# STM32H503 register map
File version: 1.5
CPU: CM33 r0p0, little endian, MPU, FPU, 4 interrupt priority bits
Registers are 32-bit, read-write, reset 0x0 unless marked. A register's access mark holds for its fields unless they carry their own. Offsets are from the block's base; [hi:lo] are bit positions; 'fields as' and 'values as' point back to an identical list.

## RCC (part 2 of 2) — Reset and clock controller
Base 0x44020C00
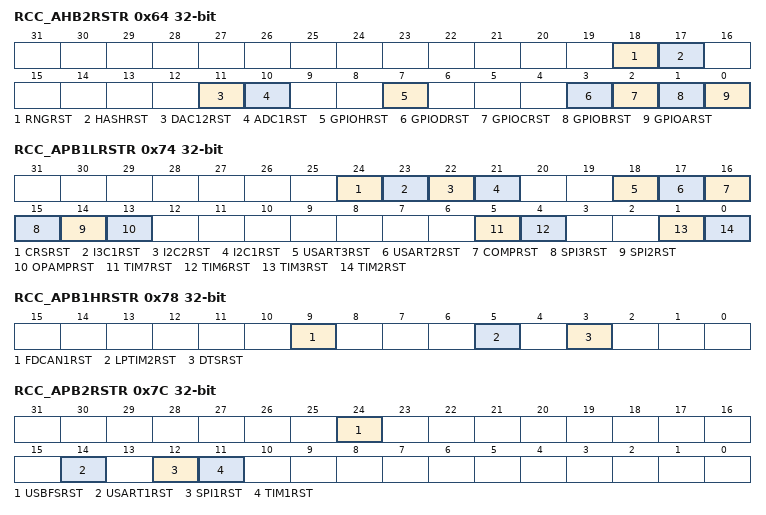
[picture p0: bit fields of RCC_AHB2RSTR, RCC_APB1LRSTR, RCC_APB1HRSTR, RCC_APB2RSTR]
0x64 RCC_AHB2RSTR — RCC AHB2 peripheral reset register
  [18] RNGRST — RNG block reset Set and reset by software.
    0=does not reset RNG block (default after reset); 1=resets RNG block
  [17] HASHRST — HASH block reset Set and reset by software.
    0=does not reset HASH block (default after reset); 1=resets HASH block
  [11] DAC12RST — DAC block reset Set and reset by software.
    0=does not reset DAC block (default after reset); 1=resets DAC block
  [10] ADC1RST — ADC1 block reset Set and reset by software.
    0=does not reset ADC1 block (default after reset); 1=resets ADC1 block
  [7] GPIOHRST — GPIOH block reset Set and reset by software.
    0=does not reset the GPIOH block (default after reset); 1=resets the GPIOH block
  [3] GPIODRST — GPIOD block reset Set and reset by software.
    0=does not reset the GPIOD block (default after reset); 1=resets the GPIOD block
  [2] GPIOCRST — GPIOC block reset Set and reset by software.
    0=does not reset the GPIOC block (default after reset); 1=resets the GPIOC block
  [1] GPIOBRST — GPIOB block reset Set and reset by software.
    0=does not reset the GPIOB block (default after reset); 1=resets the GPIOB block
  [0] GPIOARST — GPIOA block reset Set and reset by software.
    0=does not reset the GPIOA block (default after reset); 1=resets the GPIOA block
0x74 RCC_APB1LRSTR — RCC APB1 peripheral low reset register
  [24] CRSRST — CRS block reset Set and reset by software.
    0=does not reset the CRS block (default after reset); 1=resets the CRS block
  [23] I3C1RST — I3C1 block reset Set and reset by software.
    0=does not reset the I3C1 block (default after reset); 1=resets the I3C1 block
  [22] I2C2RST — I2C2 block reset Set and reset by software.
    0=does not reset the I2C2 block (default after reset); 1=resets the I2C2 block
  [21] I2C1RST — I2C1 block reset Set and reset by software.
    0=does not reset the I2C1 block (default after reset); 1=resets the I2C1 block
  [18] USART3RST — USART3 block reset Set and reset by software.
    0=does not reset the USART3 block (default after reset); 1=resets the USART3 block
  [17] USART2RST — USART2 block reset Set and reset by software.
    0=does not reset the USART2 block (default after reset); 1=resets the USART2 block
  [16] COMPRST — COMP block reset Set and reset by software.
    0=does not reset the COMP block (default after reset); 1=resets the COMP block
  [15] SPI3RST — SPI3 block reset Set and reset by software.
    0=does not reset the SPI3 block (default after reset); 1=resets the SPI3 block
  [14] SPI2RST — SPI2 block reset Set and reset by software.
    0=does not reset the SPI2 block (default after reset); 1=resets the SPI2 block
  [13] OPAMPRST — OPAMP block reset Set and reset by software.
    0=does not reset the OPAMP block (default after reset); 1=resets the OPAMP block
  [5] TIM7RST — TIM7 block reset Set and reset by software.
    0=does not reset the TIM7 block (default after reset); 1=resets the TIM7 block
  [4] TIM6RST — TIM6 block reset Set and reset by software.
    0=does not reset the TIM6 block (default after reset); 1=resets the TIM6 block
  [1] TIM3RST — TIM3 block reset Set and reset by software.
    0=does not reset the TIM3 block (default after reset); 1=resets the TIM3 block
  [0] TIM2RST — TIM2 block reset Set and reset by software.
    0=does not reset the TIM2 block (default after reset); 1=resets the TIM2 block
0x78 RCC_APB1HRSTR — RCC APB1 peripheral high reset register
  [9] FDCAN1RST — FDCAN1 block reset Set and reset by software.
    0=does not reset the FDCAN1 block (default after reset); 1=resets the FDCAN1 block
  [5] LPTIM2RST — LPTIM2 block reset Set and reset by software.
    0=does not reset the LPTIM2 block (default after reset); 1=resets the LPTIM2 block
  [3] DTSRST — DTS block reset Set and reset by software.
    0=does not reset the DTS block (default after reset); 1=resets the DTS block
0x7C RCC_APB2RSTR — RCC APB2 peripheral reset register
  [24] USBFSRST — USBFS block reset Set and reset by software.
    0=does not reset the USBFS block (default after reset); 1=resets the USBFS block
  [14] USART1RST — USART1 block reset Set and reset by software.
    0=does not reset the USART1 block (default after reset); 1=resets the USART1 block
  [12] SPI1RST — SPI1 block reset Set and reset by software.
    0=does not reset the SPI1 block (default after reset); 1=resets the SPI1 block
  [11] TIM1RST — TIM1 block reset Set and reset by software.
    0=does not reset the TIM1 block (default after reset); 1=resets the TIM1 block
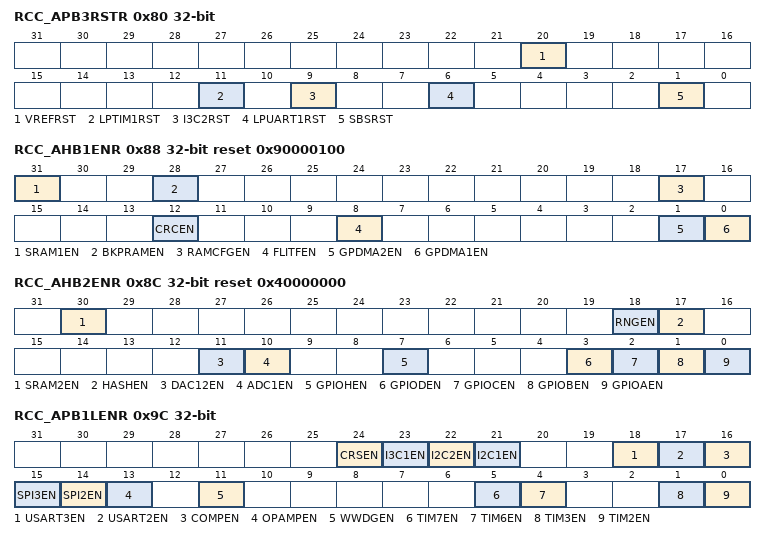
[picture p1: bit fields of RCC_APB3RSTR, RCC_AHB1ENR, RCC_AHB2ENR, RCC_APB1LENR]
0x80 RCC_APB3RSTR — RCC APB3 peripheral reset register
  [20] VREFRST — VREF block reset Set and reset by software.
    0=does not reset the VREF block (default after reset); 1=resets the VREF block
  [11] LPTIM1RST — LPTIM1 block reset Set and reset by software.
    0=does not reset the LPTIM1 block (default after reset); 1=resets the LPTIM1 block
  [9] I3C2RST — I3C2RST block reset Set and reset by software.
    0=does not reset the I3C2RST block (default after reset); 1=resets the I3C2RST block
  [6] LPUART1RST — LPUART1 block reset Set and reset by software.
    0=does not reset the LPUART1 block (default after reset); 1=resets the LPUART1 block
  [1] SBSRST — SBS block reset Set and reset by software.
    0=does not reset the SBS block (default after reset); 1=resets the SBS block
0x88 RCC_AHB1ENR reset 0x90000100 — RCC AHB1 peripherals clock register
  [31] SRAM1EN — SRAM1 clock enable Set and reset by software.
    0=SRAM1 clock disabled; 1=SRAM1 clock enabled (default after reset)
  [28] BKPRAMEN — BKPRAM clock enable Set and reset by software
    0=BKPRAM peripheral clock disabled (default after reset); 1=BKPRAM peripheral clock enabled
  [17] RAMCFGEN — RAMCFG clock enable Set and reset by software.
    0=RAMCFG peripheral clock disabled (default after reset); 1=RAMCFG peripheral clock enabled
  [12] CRCEN — CRC clock enable Set and reset by software.
    0=CRC peripheral clock disabled (default after reset); 1=CRC peripheral clock enabled
  [8] FLITFEN — Flash interface clock enable Set and reset by software.
    0=FLASH interface clock disabled; 1=FLASH interface clock enabled (default after reset)
  [1] GPDMA2EN — GPDMA2 clock enable Set and reset by software.
    0=GPDMA2 peripheral clock disabled (default after reset); 1=GPDMA2 peripheral clock enabled
  [0] GPDMA1EN — GPDMA1 clock enable Set and reset by software.
    0=GPDMA1 peripheral clock disabled (default after reset); 1=GPDMA1 peripheral clock enabled
0x8C RCC_AHB2ENR reset 0x40000000 — RCC AHB2 peripheral clock register
  [30] SRAM2EN — SRAM2 clock enable Set and reset by software.
    0=SRAM2 clock disabled; 1=SRAM2 clock enabled (default after reset)
  [18] RNGEN — RNG clock enable Set and reset by software.
    0=RNG peripheral clock disabled (default after reset); 1=RNG peripheral clock enabled
  [17] HASHEN — HASH clock enable Set and reset by software.
    0=HASH peripheral clock disabled (default after reset); 1=HASH peripheral clock enabled
  [11] DAC12EN — DAC clock enable Set and reset by software.
    0=DAC peripheral clock disabled (default after reset); 1=DAC peripheral clock enabled
  [10] ADC1EN — ADC1 peripherals clock enabled Set and reset by software.
    0=ADC1 peripherals clock disabled (default after reset); 1=ADC1 peripherals clock enabled
  [7] GPIOHEN — GPIOH clock enable Set and reset by software.
    0=GPIOH peripheral clock disabled (default after reset); 1=GPIOH peripheral clock enabled
  [3] GPIODEN — GPIOD clock enable Set and reset by software.
    0=GPIOD peripheral clock disabled (default after reset); 1=GPIOD peripheral clock enabled
  [2] GPIOCEN — GPIOC clock enable Set and reset by software.
    0=GPIOC peripheral clock disabled (default after reset); 1=GPIOC peripheral clock enabled
  [1] GPIOBEN — GPIOB clock enable Set and reset by software.
    0=GPIOB peripheral clock disabled (default after reset); 1=GPIOB peripheral clock enabled
  [0] GPIOAEN — GPIOA clock enable Set and reset by software.
    0=GPIOA peripheral clock disabled (default after reset); 1=GPIOA peripheral clock enabled
0x9C RCC_APB1LENR — RCC APB1 peripheral clock register
  [24] CRSEN — CRS clock enable Set and reset by software.
    0=CRS peripheral clock disabled (default after reset); 1=CRS peripheral clock enabled
  [23] I3C1EN — I3C1 clock enable Set and reset by software.
    0=I3C1 peripheral clock disabled (default after reset); 1=I3C1 peripheral clock enabled
  [22] I2C2EN — I2C2 clock enable Set and reset by software.
    0=I2C2 peripheral clock disabled (default after reset); 1=I2C2 peripheral clock enabled
  [21] I2C1EN — I2C1 clock enable Set and reset by software.
    0=I2C1 peripheral clock disabled (default after reset); 1=I2C1 peripheral clock enabled
  [18] USART3EN — USART3 clock enable Set and reset by software.
    0=USART3 peripheral clock disabled (default after reset); 1=USART3 peripheral clock enabled
  [17] USART2EN — USART2 clock enable Set and reset by software.
    0=USART2 peripheral clock disabled (default after reset); 1=USART2 peripheral clock enabled
  [16] COMPEN — COMP clock enable Set and reset by software.
    0=COMP peripheral clock disabled (default after reset); 1=COMP peripheral clock enabled
  [15] SPI3EN — SPI3 clock enable Set and reset by software.
    0=SPI3 peripheral clock disabled (default after reset); 1=SPI3 peripheral clock enabled
  [14] SPI2EN — SPI2 clock enable Set and reset by software.
    0=SPI2 peripheral clock disabled (default after reset); 1=SPI2 peripheral clock enabled
  [13] OPAMPEN — OPAMP clock enable Set and reset by software.
    0=OPAMP peripheral clock disabled (default after reset); 1=OPAMP peripheral clock enabled
  [11] WWDGEN — WWDG clock enable Set and reset by software.
    0=WWDG peripheral clock disabled (default after reset); 1=WWDG peripheral clock enabled
  [5] TIM7EN — TIM7 clock enable Set and reset by software.
    0=TIM7 peripheral clock disabled (default after reset); 1=TIM7 peripheral clock enabled
  [4] TIM6EN — TIM6 clock enable Set and reset by software.
    0=TIM6 peripheral clock disabled (default after reset); 1=TIM6 peripheral clock enabled
  [1] TIM3EN — TIM3 clock enable Set and reset by software.
    0=TIM3 peripheral clock disabled (default after reset); 1=TIM3 peripheral clock enabled
  [0] TIM2EN — TIM2 clock enable Set and reset by software.
    0=TIM2 peripheral clock disabled (default after reset); 1=TIM2 peripheral clock enabled
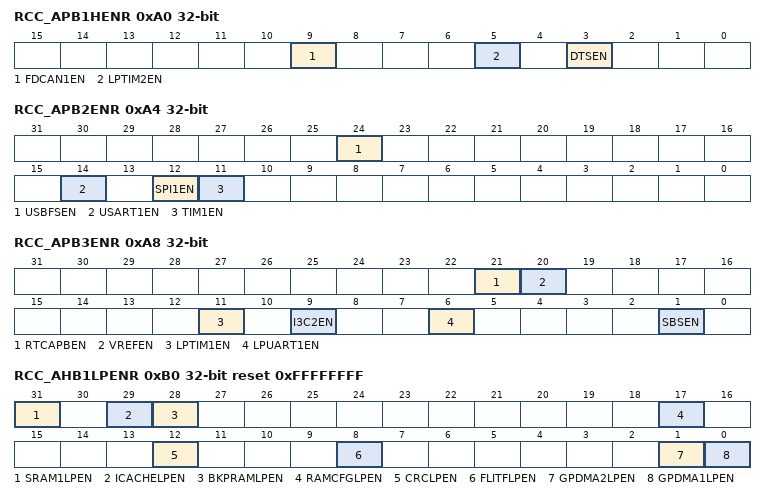
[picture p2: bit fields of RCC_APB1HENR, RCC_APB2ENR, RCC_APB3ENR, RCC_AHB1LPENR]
0xA0 RCC_APB1HENR — RCC APB1 peripheral clock register
  [9] FDCAN1EN — FDCAN1 peripheral clock enable Set and reset by software.
    0=FDCAN1 peripheral clock disabled (default after reset); 1=FDCAN1 peripheral clock enabled
  [5] LPTIM2EN — LPTIM2 clock enable Set and reset by software.
    0=LPTIM2 peripheral clock disabled (default after reset); 1=LPTIM2 peripheral clock enabled
  [3] DTSEN — DTS clock enable Set and reset by software.
    0=DTS peripheral clock disabled (default after reset); 1=DTS peripheral clock enabled
0xA4 RCC_APB2ENR — RCC APB2 peripheral clock register
  [24] USBFSEN — USBFS clock enable Set and reset by software.
    0=USBFS peripheral clock disabled (default after reset); 1=USBFS peripheral clock enabled
  [14] USART1EN — USART1 clock enable Set and reset by software.
    0=USART1 peripheral clock disabled (default after reset); 1=USART1 peripheral clock enabled
  [12] SPI1EN — SPI1 clock enable Set and reset by software.
    0=SPI1 peripheral clock disabled (default after reset); 1=SPI1 peripheral clock enabled
  [11] TIM1EN — TIM1 clock enable Set and reset by software.
    0=TIM1 peripheral clock disabled (default after reset); 1=TIM1 peripheral clock enabled
0xA8 RCC_APB3ENR — RCC APB3 peripheral clock register
  [21] RTCAPBEN — RTC APB interface clock enable Set and reset by software.
    0=RTC APB interface clock disabled (default after reset); 1=RTC APB interface clock enabled
  [20] VREFEN — VREF clock enable Set and reset by software.
    0=VREF peripheral clock disabled (default after reset); 1=VREF peripheral clock enabled
  [11] LPTIM1EN — LPTIM1 clock enable Set and reset by software.
    0=LPTIM1 peripheral clock disabled (default after reset); 1=LPTIM1 peripheral clock enabled
  [9] I3C2EN — I3C2EN clock enable Set and reset by software.
    0=I3C2EN peripheral clock disabled (default after reset); 1=I3C2EN peripheral clock enabled
  [6] LPUART1EN — LPUART1 clock enable Set and reset by software.
    0=LPUART1 peripheral clock disabled (default after reset); 1=LPUART1 peripheral clock enabled
  [1] SBSEN — SBS clock enable Set and reset by software.
    0=SBS peripheral clock disabled (default after reset); 1=SBS peripheral clock enabled
0xB0 RCC_AHB1LPENR reset 0xFFFFFFFF — RCC AHB1 sleep clock register
  [31] SRAM1LPEN — SRAM1 clock enable during sleep mode Set and reset by software
    0=SRAM1 peripheral clock disabled during sleep mode; 1=SRAM1 peripheral clock enabled during sleep mode (default after reset)
  [29] ICACHELPEN — ICACHE clock enable during sleep mode Set and reset by software
    0=ICACHE peripheral clock disabled during sleep mode; 1=ICACHE peripheral clock enabled during sleep mode (default after reset)
  [28] BKPRAMLPEN — BKPRAM clock enable during sleep mode Set and reset by software
    0=BKPRAM peripheral clock disabled during sleep mode; 1=BKPRAM peripheral clock enabled during sleep mode (default after reset)
  [17] RAMCFGLPEN — RAMCFG clock enable during sleep mode Set and reset by software.
    0=RAMCFG peripheral clock disabled during sleep mode; 1=RAMCFG peripheral clock enabled during sleep mode (default after reset)
  [12] CRCLPEN — CRC clock enable during sleep mode Set and reset by software.
    0=CRC peripheral clock disabled during sleep mode; 1=CRC peripheral clock enabled during sleep mode (default after reset)
  [8] FLITFLPEN — Flash interface (FLITF) clock enable during sleep mode Set and reset by software.
    0=FLITF peripheral clock disabled during sleep mode; 1=FLITF peripheral clock enabled during sleep mode (default after reset)
  [1] GPDMA2LPEN — GPDMA2 clock enable during sleep mode Set and reset by software.
    0=GPDMA2 peripheral clock disabled during sleep mode; 1=GPDMA2 peripheral clock enabled during sleep mode (default after reset)
  [0] GPDMA1LPEN — GPDMA1 clock enable during sleep mode Set and reset by software.
    0=GPDMA1 peripheral clock disabled during sleep mode; 1=GPDMA1 peripheral clock enabled during sleep mode (default after reset)
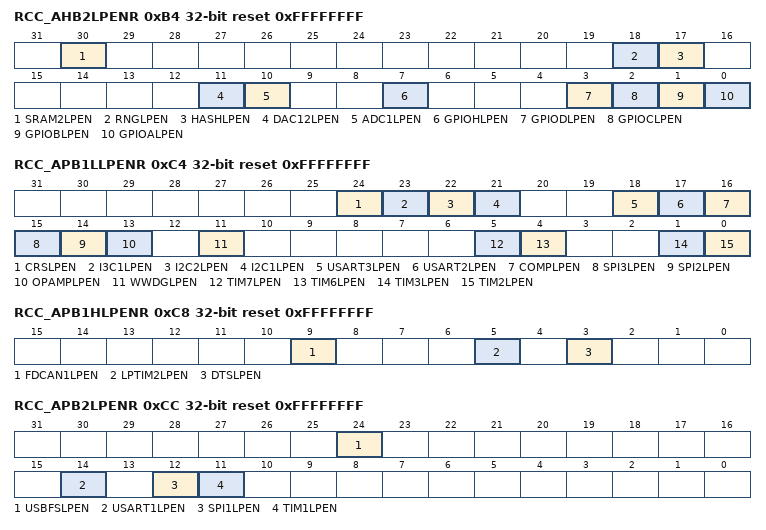
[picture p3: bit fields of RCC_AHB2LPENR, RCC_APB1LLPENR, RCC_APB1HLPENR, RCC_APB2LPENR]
0xB4 RCC_AHB2LPENR reset 0xFFFFFFFF — RCC AHB2 sleep clock register
  [30] SRAM2LPEN — SRAM2 clock enable during sleep mode Set and reset by software.
    0=SRAM2 peripheral clock disabled during sleep mode; 1=SRAM2 peripheral clock enabled during sleep mode (default after reset)
  [18] RNGLPEN — RNG clock enable during sleep mode Set and reset by software.
    0=RNG peripheral clock disabled during sleep mode; 1=RNG peripheral clock enabled during sleep mode (default after reset)
  [17] HASHLPEN — HASH clock enable during sleep mode Set and reset by software.
    0=HASH peripheral clock disabled during sleep mode; 1=HASH peripheral clock enabled during sleep mode (default after reset)
  [11] DAC12LPEN — DAC clock enable during sleep mode Set and reset by software.
    0=DAC peripheral clock disabled during sleep mode; 1=DAC peripheral clock enabled during sleep mode (default after reset)
  [10] ADC1LPEN — ADC1 peripherals clock enable during sleep mode Set and reset by software.
    0=ADC1 peripherals clock disabled during sleep mode; 1=ADC1 peripherals clock enabled during sleep mode (default after reset)
  [7] GPIOHLPEN — GPIOH clock enable during sleep mode Set and reset by software.
    0=GPIOH peripheral clock disabled during sleep mode; 1=GPIOH peripheral clock enabled during sleep mode (default after reset)
  [3] GPIODLPEN — GPIOD clock enable during sleep mode Set and reset by software.
    0=GPIOD peripheral clock disabled during sleep mode; 1=GPIOD peripheral clock enabled during sleep mode (default after reset)
  [2] GPIOCLPEN — GPIOC clock enable during sleep mode Set and reset by software.
    0=GPIOC peripheral clock disabled during sleep mode; 1=GPIOC peripheral clock enabled during sleep mode (default after reset)
  [1] GPIOBLPEN — GPIOB clock enable during sleep mode Set and reset by software.
    0=GPIOB peripheral clock disabled during sleep mode; 1=GPIOB peripheral clock enabled during sleep mode (default after reset)
  [0] GPIOALPEN — GPIOA clock enable during sleep mode Set and reset by software.
    0=GPIOA peripheral clock disabled during sleep mode; 1=GPIOA peripheral clock enabled during sleep mode (default after reset)
0xC4 RCC_APB1LLPENR reset 0xFFFFFFFF — RCC APB1 sleep clock register
  [24] CRSLPEN — CRS clock enable during sleep mode Set and reset by software.
    0=CRS peripheral clock disabled during sleep mode; 1=CRS peripheral clock enabled during sleep mode (default after reset)
  [23] I3C1LPEN — I3C1 clock enable during sleep mode Set and reset by software.
    0=I3C1 peripheral clock disabled during sleep mode; 1=I3C1 peripheral clock enabled during sleep mode (default after reset)
  [22] I2C2LPEN — I2C2 clock enable during sleep mode Set and reset by software.
    0=I2C2 peripheral clock disabled during sleep mode; 1=I2C2 peripheral clock enabled during sleep mode (default after reset)
  [21] I2C1LPEN — I2C1 clock enable during sleep mode Set and reset by software.
    0=I2C1 peripheral clock disabled during sleep mode; 1=I2C1 peripheral clock enabled during sleep mode (default after reset)
  [18] USART3LPEN — USART3 clock enable during sleep mode Set and reset by software.
    0=USART3 peripheral clock disabled during sleep mode; 1=USART3 peripheral clock enabled during sleep mode (default after reset)
  [17] USART2LPEN — USART2 clock enable during sleep mode Set and reset by software.
    0=USART2 peripheral clock disabled during sleep mode; 1=USART2 peripheral clock enabled during sleep mode (default after reset)
  [16] COMPLPEN — COMP clock enable during sleep mode Set and reset by software.
    0=COMP peripheral clock disabled during sleep mode; 1=COMP peripheral clock enabled during sleep mode (default after reset)
  [15] SPI3LPEN — SPI3 clock enable during sleep mode Set and reset by software.
    0=SPI3 peripheral clock disabled during sleep mode; 1=SPI3 peripheral clock enabled during sleep mode (default after reset)
  [14] SPI2LPEN — SPI2 clock enable during sleep mode Set and reset by software.
    0=SPI2 peripheral clock disabled during sleep mode; 1=SPI2 peripheral clock enabled during sleep mode (default after reset)
  [13] OPAMPLPEN — OPAMP clock enable during sleep mode Set and reset by software.
    0=OPAMP peripheral clock disabled during sleep mode; 1=OPAMP peripheral clock enabled during sleep mode (default after reset)
  [11] WWDGLPEN — WWDG clock enable during sleep mode Set and reset by software.
    0=WWDG peripheral clock disabled during sleep mode; 1=WWDG peripheral clock enabled during sleep mode (default after reset)
  [5] TIM7LPEN — TIM7 clock enable during sleep mode Set and reset by software.
    0=TIM7 peripheral clock disabled during sleep mode; 1=TIM7 peripheral clock enabled during sleep mode (default after reset)
  [4] TIM6LPEN — TIM6 clock enable during sleep mode Set and reset by software.
    0=TIM6 peripheral clock disabled during sleep mode; 1=TIM6 peripheral clock enabled during sleep mode (default after reset)
  [1] TIM3LPEN — TIM3 clock enable during sleep mode Set and reset by software.
    0=TIM3 peripheral clock disabled during sleep mode; 1=TIM3 peripheral clock enabled during sleep mode (default after reset)
  [0] TIM2LPEN — TIM2 clock enable during sleep mode Set and reset by software.
    0=TIM2 peripheral clock disabled during sleep mode; 1=TIM2 peripheral clock enabled during sleep mode (default after reset)
0xC8 RCC_APB1HLPENR reset 0xFFFFFFFF — RCC APB1 sleep clock register
  [9] FDCAN1LPEN — FDCAN1 peripheral clock enable during sleep mode Set and reset by software.
    0=FDCAN1 peripheral clock disabled during sleep mode; 1=FDCAN1 peripheral clock enabled during sleep mode (default after reset)
  [5] LPTIM2LPEN — LPTIM2 clock enable during sleep mode Set and reset by software.
    0=LPTIM2 peripheral clock disabled during sleep mode; 1=LPTIM2 peripheral clock enabled during sleep mode (default after reset)
  [3] DTSLPEN — DTS clock enable during sleep mode Set and reset by software.
    0=DTS peripheral clock disabled during sleep mode; 1=DTS peripheral clock enabled during sleep mode (default after reset)
0xCC RCC_APB2LPENR reset 0xFFFFFFFF — RCC APB2 sleep clock register
  [24] USBFSLPEN — USBFS clock enable during sleep mode Set and reset by software.
    0=USBFS peripheral clock disabled during sleep mode; 1=USBFS peripheral clock enabled during sleep mode (default after reset)
  [14] USART1LPEN — USART1 clock enable during sleep mode Set and reset by software.
    0=USART1 peripheral clock disabled during sleep mode; 1=USART1 peripheral clock enabled during sleep mode (default after reset)
  [12] SPI1LPEN — SPI1 clock enable during sleep mode Set and reset by software.
    0=SPI1 peripheral clock disabled during sleep mode; 1=SPI1 peripheral clock enabled during sleep mode (default after reset)
  [11] TIM1LPEN — TIM1 clock enable during sleep mode Set and reset by software.
    0=TIM1 peripheral clock disabled during sleep mode; 1=TIM1 peripheral clock enabled during sleep mode (default after reset)
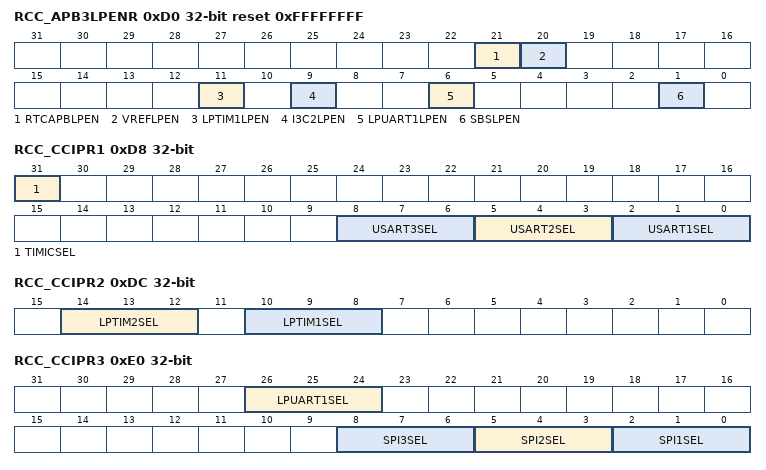
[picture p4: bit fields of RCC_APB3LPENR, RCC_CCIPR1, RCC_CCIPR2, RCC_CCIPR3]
0xD0 RCC_APB3LPENR reset 0xFFFFFFFF — RCC APB3 sleep clock register
  [21] RTCAPBLPEN — RTC APB interface clock enable during sleep mode Set and reset by software.
    0=RTC APB interface clock disabled during sleep mode; 1=RTC APB interface clock enabled during sleep mode (default after reset)
  [20] VREFLPEN — VREF clock enable during sleep mode Set and reset by software.
    0=VREF peripheral clock disabled during sleep mode; 1=VREF peripheral clock enabled during sleep mode (default after reset)
  [11] LPTIM1LPEN — LPTIM1 clock enable during sleep mode Set and reset by software.
    0=LPTIM1 peripheral clock disabled during sleep mode; 1=LPTIM1 peripheral clock enabled during sleep mode (default after reset)
  [9] I3C2LPEN — I3C2 clock enable during sleep mode Set and reset by software.
    0=I3C2 peripheral clock disabled during sleep mode; 1=I3C2 peripheral clock enabled during sleep mode (default after reset)
  [6] LPUART1LPEN — LPUART1 clock enable during sleep mode Set and reset by software.
    0=LPUART1 peripheral clock disabled during sleep mode; 1=LPUART1 peripheral clock enabled during sleep mode (default after reset)
  [1] SBSLPEN — SBS clock enable during sleep mode Set and reset by software.
    0=SBS peripheral clock disabled during sleep mode; 1=SBS peripheral clock enabled during sleep mode (default after reset)
0xD8 RCC_CCIPR1 — RCC kernel clock configuration register
  [31] TIMICSEL — TIM2, TIM3 and LPTIM2 input capture source selection Set and reset by software.
    0=No internal clock available for timers input capture (default after reset); 1=hsi_ker_ck/1024, hsi_ker_ck/8 and csi_ker_ck/128 selected for timers input capture
  [8:6] USART3SEL — USART3 kernel clock source selection Set and reset by software. others: reserved, the kernel clock is disabled
    0=rcc_pclk1 selected as kernel clock (default after reset); 1=pll2_q_ck selected as kernel clock; 3=hsi_ker_ck selected as kernel clock; 4=csi_ker_ck selected as kernel clock; 5=lse_ck selected as kernel clock
  [5:3] USART2SEL — USART2 kernel clock source selection Set and reset by software. others: reserved, the kernel clock is disabled
    values as USART3SEL
  [2:0] USART1SEL — USART1 kernel clock source selection Set and reset by software. others: reserved, the kernel clock is disabled
    0=rcc_pclk2 selected as kernel clock (default after reset); 1=pll2_q_ck selected as kernel clock; 3=hsi_ker_ck selected as kernel clock; 4=csi_ker_ck selected as kernel clock; 5=lse_ck selected as kernel clock
0xDC RCC_CCIPR2 — RCC kernel clock configuration register
  [14:12] LPTIM2SEL — LPTIM2 kernel clock source selection others: reserved, the kernel clock is disabled
    0=rcc_pclk1 selected as kernel clock (default after reset); 1=pll2_p_ck selected as kernel clock; 3=lse_ker_ck selected as kernel clock; 4=lsi_ker_ck selected as kernel clock; 5=per_ck selected as kernel clock
  [10:8] LPTIM1SEL — LPTIM1 kernel clock source selection others: reserved, the kernel clock is disabled
    0=rcc_pclk3 selected as kernel clock (default after reset); 1=pll2_p_ck selected as kernel clock; 3=lse_ker_ck selected as kernel clock; 4=lsi_ker_ck selected as kernel clock; 5=per_ck selected as kernel clock
0xE0 RCC_CCIPR3 — RCC kernel clock configuration register
  [26:24] LPUART1SEL — LPUART1 kernel clock source selection others: reserved, the kernel clock is disabled
    0=rcc_pclk3 s elected as kernel clock (default after reset); 1=pll2_q_ck selected as kernel clock; 3=hsi_ker_ck selected as kernel clock; 4=csi_ker_ck selected as kernel clock; 5=lse_ck selected as kernel clock
  [8:6] SPI3SEL — SPI3 kernel clock source selection Set and reset by software. others: reserved, the kernel clock is disabled
    0=pll1_q_ck selected as kernel clock (default after reset); 1=pll2_p_ck selected as kernel clock; 3=AUDIOCLK selected as kernel clock; 4=per_ck selected as kernel clock
  [5:3] SPI2SEL — SPI2 kernel clock source selection Set and reset by software. others: reserved, the kernel clock is disabled
    values as SPI3SEL
  [2:0] SPI1SEL — SPI1 kernel clock source selection Set and reset by software. others: reserved, the kernel clock is disabled
    values as SPI3SEL
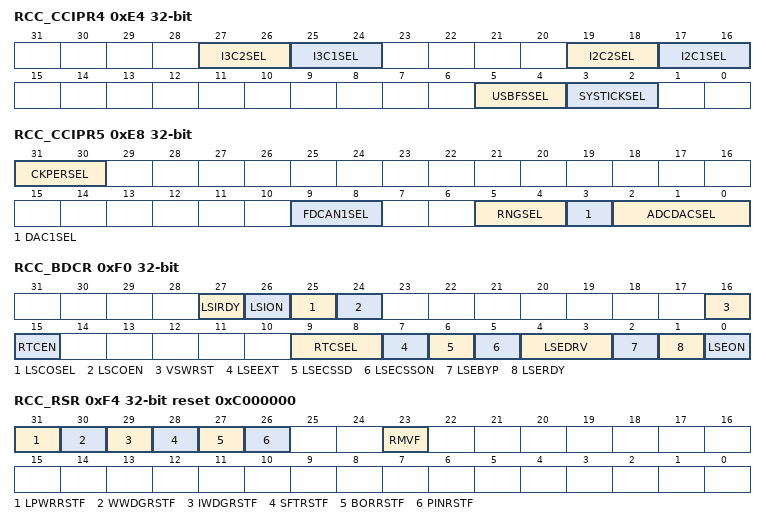
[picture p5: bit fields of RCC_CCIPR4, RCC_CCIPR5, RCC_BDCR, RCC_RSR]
0xE4 RCC_CCIPR4 — RCC kernel clock configuration register
  [27:26] I3C2SEL — I3C2 kernel clock source selection
    0=rcc_pclk3 selected as kernel clock (default after reset); 1=pll2_r_ck selected as kernel clock; 2=hsi_ker_ck selected as kernel clock; 3=no clock selected
  [25:24] I3C1SEL — I3C1 kernel clock source selection
    values as I3C2SEL
  [19:18] I2C2SEL — I2C2 kernel clock source selection
    0=rcc_pclk1 selected as kernel clock (default after reset); 1=pll2_r_ck selected as kernel clock; 2=hsi_ker_ck selected as kernel clock; 3=csi_ker_ck selected as kernel clock
  [17:16] I2C1SEL — I2C1 kernel clock source selection
    values as I2C2SEL
  [5:4] USBFSSEL — USBFS kernel clock source selection
    0=no clock is selected as kernel clock (default after reset); 1=pll1_q_ck selected as kernel clock; 2=pll2_q_ck selected as kernel clock; 3=hsi48_ker_ck selected as kernel clock
  [3:2] SYSTICKSEL — SYSTICK clock source selection Note: rcc_hclk frequency must be four times higher than lsi_ker_ck/lse_ck (period (LSI/LSE) greater than or equal 4 * period (HCLK).
    0=rcc_hclk/8 selected as clock source (default after reset); 1=lsi_ker_ck[1] selected as clock source; 2=lse_ck[1] selected as clock source; 3=reserved, the kernel clock is disabled
0xE8 RCC_CCIPR5 — RCC kernel clock configuration register
  [31:30] CKPERSEL — per_ck clock source selection
    0=hsi_ker_ck selected as kernel clock (default after reset); 1=csi_ker_ck selected as kernel clock; 2=hse_ck selected as kernel clock; 3=reserved, the per_ck clock is disabled
  [9:8] FDCAN1SEL — FDCAN1 kernel clock source selection
    0=hse_ck selected as kernel clock (default after reset); 1=pll1_q_ck selected as kernel clock; 2=pll2_q_ck selected as kernel clock; 3=reserved, the kernel clock is disabled
  [5:4] RNGSEL — RNG kernel clock source selection
    0=hsi48_ker_ck selected as kernel clock (default after reset); 1=pll1_q_ck selected as kernel clock; 2=lse_ck selected as kernel clock; 3=lsi_ker_ck selected as kernel clock
  [3] DAC1SEL — DAC1 sample and hold clock source selection
    0=dac_hold_ck selected as kernel clock (default after reset); 1=dac_hold_ck selected as kernel clock
  [2:0] ADCDACSEL — ADC and DAC kernel clock source selection others: reserved, the kernel clock is disabled
    0=rcc_hclk selected as kernel clock (default after reset); 1=sys_ck selected as kernel clock; 2=pll2_r_ck selected as kernel clock; 3=hse_ck selected as kernel clock; 4=hsi_ker_ck selected as kernel clock; 5=csi_ker_ck selected as kernel clock
0xF0 RCC_BDCR — RCC Backup domain control register
  [27] LSIRDY — LSI oscillator ready Set and cleared by hardware to indicate when the LSI oscillator is stable. After the LSION bit is cleared, LSIRDY goes low after three internal low-speed oscillator clock cycles. This bit is set when the LSI is used by IWDG or RTC, even if LSION = 0.
    0=LSI oscillator not ready; 1=LSI oscillator ready
  [26] LSION — LSI oscillator enable Set and cleared by software.
    0=LSI oscillator off; 1=LSI oscillator on
  [25] LSCOSEL — Low-speed clock output selection Set and cleared by software.
    0=LSI clock selected; 1=LSE clock selected
  [24] LSCOEN — Low-speed clock output (LSCO) enable Set and cleared by software.
    0=LSCO output disabled; 1=LSCO output enabled
  [16] VSWRST — VSwitch domain software reset Set and reset by software.
    0=reset not activated (default after Backup domain reset); 1=resets the entire VSW domain
  [15] RTCEN — RTC clock enable Set and reset by software.
    0=rtc_ck disabled (default after Backup domain reset); 1=rtc_ck enabled
  [9:8] RTCSEL — RTC clock source selection Set by software to select the clock source for the RTC. These bits can be written only one time (except in case of failure detection on LSE). These bits must be written before LSECSSON is enabled. The VSWRST bit can be used to reset them, then it can be written one time again. If HSE is selected as RTC clock, this clock is lost when the system is in Stop mode or in case of a pin reset (NRST).
    0=no clock (default after Backup domain reset); 1=LSE selected as RTC clock; 2=LSI selected as RTC clock; 3=HSE divided by RTCPRE value selected as RTC clock
  [7] LSEEXT — low-speed external clock type in bypass mode Set and reset by software to select the external clock type (analog or digital). The external clock must be enabled with the LSEON bit, to be used by the device. The LSEEXT bit can be written only if the LSE oscillator is disabled.
    0=LSE in analog mode (default after Backup domain reset); 1=LSE in digital mode (do not use if RTC is active)
  [6] LSECSSD — LSE clock security system failure detection Set by hardware to indicate when a failure has been detected by the clock security system on the external 32 kHz oscillator.
    0=no failure detected on 32 kHz oscillator (default after Backup domain reset); 1=failure detected on 32 kHz oscillator
  [5] LSECSSON — LSE clock security system enable Set by software to enable the clock security system on 32 kHz oscillator. LSECSSON must be enabled after LSE is enabled (LSEON enabled) and ready (LSERDY set by hardware) and after RTCSEL is selected. Once enabled, this bit cannot be disabled, except after a LSE failure detection (LSECSSD = 1). In that case the software must disable LSECSSON.
    0=CSS on 32 kHz oscillator OFF (default after Backup domain reset); 1=CSS on 32 kHz oscillator ON
  [4:3] LSEDRV — LSE oscillator driving capability Set by software to select the driving capability of the LSE oscillator. These bit can be written only if LSE oscillator is disabled (LSEON = 0 and LSERDY = 0).
    0=lowest drive (default after Backup domain reset); 1=medium-low drive; 2=medium-high drive; 3=highest drive
  [2] LSEBYP — LSE oscillator bypass Set and reset by software to bypass oscillator in debug mode. This bit must not be written when the LSE is enabled (by LSEON) or ready (LSERDY = 1)
    0=LSE oscillator not bypassed (default after Backup domain reset); 1=LSE oscillator bypassed
  [1] LSERDY — LSE oscillator ready Set and reset by hardware to indicate when the LSE is stable. This bit needs 6 cycles of lse_ck clock to fall down after LSEON has been set to 0.
    0=LSE oscillator not ready (default after Backup domain reset); 1=LSE oscillator ready
  [0] LSEON — LSE oscillator enabled Set and reset by software.
    0=LSE oscillator OFF (default after Backup domain reset); 1=LSE oscillator ON
0xF4 RCC_RSR reset 0xC000000 — RCC reset status register
  [31] LPWRRSTF — Low-power reset flag Set by hardware when a reset occurs due to Stop or Standby mode entry, whereas the corresponding nRST_STOP, nRST_STBY option bit is cleared. Cleared by writing to the RMVF bit.
    0=No illegal low-power mode reset occurred; 1=Illegal low-power mode reset occurred
  [30] WWDGRSTF — window watchdog reset flag Reset by software by writing the RMVF bit. Set by hardware when a window watchdog reset occurs.
    0=no window watchdog reset occurred from WWDG (default after power-on reset); 1=window watchdog reset occurred from WWDG
  [29] IWDGRSTF — independent watchdog reset flag Reset by software by writing the RMVF bit. Set by hardware when an independent watchdog reset occurs.
    0=no independent watchdog reset occurred (default after power-on reset); 1=independent watchdog reset occurred
  [28] SFTRSTF — system reset from CPU reset flag Reset by software by writing the RMVF bit. Set by hardware when the system reset is due to CPU.The CPU can generate a system reset by writing SYSRESETREQ bit of AIRCR register of the core M33.
    0=no CPU software reset occurred (default after power-on reset); 1=a system reset has been generated by the CPU
  [27] BORRSTF — BOR reset flag Reset by software by writing the RMVF bit. Set by hardware when a BOR reset occurs (pwr_bor_rst).
    0=no BOR reset occurred; 1=BOR reset occurred (default after power-on reset)
  [26] PINRSTF — pin reset flag (NRST) Reset by software by writing the RMVF bit. Set by hardware when a reset from pin occurs.
    0=no reset from pin occurred; 1=reset from pin occurred (default after power-on reset)
  [23] RMVF — remove reset flag Set and reset by software to reset the value of the reset flags.
    0=reset of the reset flags not activated (default after power-on reset); 1=resets the value of the reset flags
